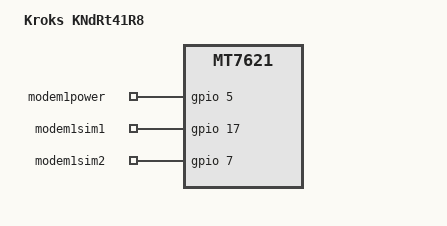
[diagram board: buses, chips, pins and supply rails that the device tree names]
#include "mt7621_kroks_v2.dtsi"

/ {
	compatible = "kroks,kndrt41r8", "mediatek,mt7621-soc";
	model = "Kroks KNdRt41R8";

	gpio_export {
		compatible = "gpio-export";
		#size-cells = <0>;

		modem1power {
			gpio-export,name = "modem1power";
			gpio-export,output = <1>;
			gpios = <&gpio 5 GPIO_ACTIVE_HIGH>;
		};

		modem1sim1 {
			gpio-export,name = "modem1sim1";
			gpio-export,output = <1>;
			gpios = <&gpio 17 GPIO_ACTIVE_HIGH>;
		};

		modem1sim2 {
			gpio-export,name = "modem1sim2";
			gpio-export,output = <0>;
			gpios = <&gpio 7 GPIO_ACTIVE_HIGH>;
		};
	};
};

&switch0 {
	ports {
		port@3 {
			status = "okay";
			label = "lan2";
		};

		port@4 {
			status = "okay";
			label = "lan1";
		};
	};
};

&state_default {
	gpio {
		groups = "jtag";
		function = "gpio";
	};
};

&xhci {
	mediatek,u2p-dis-msk = <0x2>;
};
